# RZN2L register map
Vendor: Renesas Electronics Corporation; Series: RZN; File version: 1.30.01
CPU: other r0p0, little endian, MPU, no FPU, VTOR, 4 interrupt priority bits, 624 interrupts
Registers are 32-bit, read-write, reset 0x0 unless marked. A register's access mark holds for its fields unless they carry their own. Offsets are from the block's base; [hi:lo] are bit positions; {n}, {i} and the like mark numbered series; 'fields as' and 'values as' point back to an identical list.

## ELC — Evnet Link Controller
Base 0x80090010
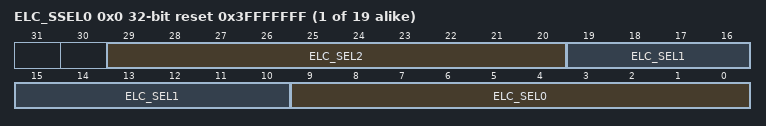
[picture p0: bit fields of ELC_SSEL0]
{0x0+4i} ELC_SSEL{i} (i=0..18) reset 0x3FFFFFFF — ELC Event Source Select Register {i}
  [29:20] ELC_SEL2 — Set the number for ELC event source to be linked to the ELC destination.
  [19:10] ELC_SEL1 — Set the number for ELC event source to be linked to the ELC destination.
  [9:0] ELC_SEL0 — Set the number for ELC event source to be linked to the ELC destination.

## DMA — DMAC Configuration
Base 0x80090060
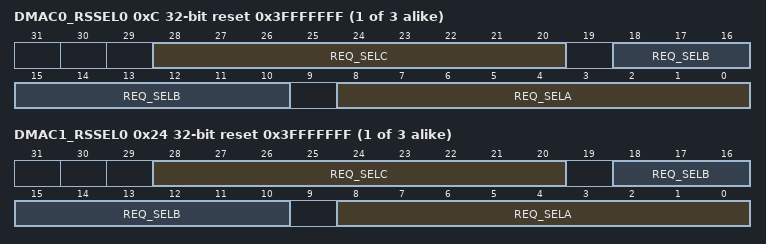
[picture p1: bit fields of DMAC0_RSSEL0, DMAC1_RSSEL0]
{0xC+4i} DMAC0_RSSEL{i} (i=0..2) reset 0x3FFFFFFF — DMAC Unit 0 Resource Select Register {i}
  [28:20] REQ_SELC — DMA Resource Select for Channel n + 2
  [18:10] REQ_SELB — DMA Resource Select for Channel n + 1
  [8:0] REQ_SELA — DMA Resource Select for Channel n
{0x24+4i} DMAC1_RSSEL{i} (i=0..2) reset 0x3FFFFFFF — DMAC Unit 1 Resource Select Register {i}
  fields as DMAC0_RSSEL0

## ESC_INI — Initial Configuration 1 for EtherCAT Slave Controller
Base 0x80110200
0x00 ECATOFFADR — EtherCAT PHY Offset Address Setting Register
  [4:0] OADD — PHY Offset Address Setting
0x04 ECATOPMOD — EtherCAT Operation Mode Register
  [0] EEPROMSIZE — EEPROM Memory Size Specification
    0=16 Kbits or less; 1=32 Kbits to 4 Mbits
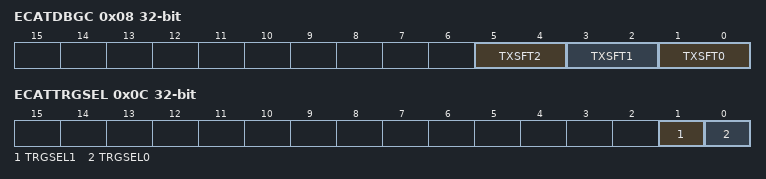
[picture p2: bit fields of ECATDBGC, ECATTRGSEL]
0x08 ECATDBGC — EtherCAT Debug Control Register
  [all] fields
    0=0 ns; 1=10 ns; 2=20 ns; 3=30 ns
  [5:4] TXSFT2 — Set the delay time for ETH2_TXEN and ETH2_TXDn of the EtherCAT
  [3:2] TXSFT1 — Set the delay time for ETH1_TXEN and ETH1_TXDn of the EtherCAT
  [1:0] TXSFT0 — Set the delay time for ETH0_TXEN and ETH0_TXDn of the EtherCAT
0x0C ECATTRGSEL — EtherCAT DC Latch Trigger Select Register
  [1] TRGSEL1 — Select DC Latch Trigger 1 for ESC
    0=Select LATCH1 input from ELC; 1=Select LATCH1 input from external
  [0] TRGSEL0 — Select DC Latch Trigger 0 for ESC
    0=Select LATCH0 input from ELC; 1=Select LATCH0 input from external

## ETHSW_PTP — Ethernet Switch for PTP
Base 0x80110400
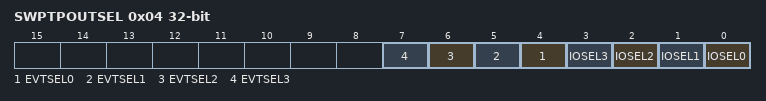
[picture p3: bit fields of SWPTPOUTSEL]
0x04 SWPTPOUTSEL — ETHSW_PTPOUT Select Register
  [n+4] EVTSEL{n} (n=0..3) — Select the source of the ETHSW_PTPOUT{n} event for GIC, DMAC, and ELC
    0=Pulse generator {n} output; 1=TDMA_GPIO[{n+4}] output
  [n] IOSEL{n} (n=0..3) — Select the source of the ETHSW_PTPOUT{n} output signal
    0=Pulse generator {n} output; 1=TDMA_GPIO[{n+4}] output
{0x400+0x100*i} SWTMEN{i} (i=0..3) — PTP Timer Pulse Output Enable {i} Register
  [0] OUTEN — Enable ETHSW_PTPOUTn Signal Output
    0=Disabled; 1=Enabled
{0x404+0x100*i} SWTMSTSEC{i} (i=0..3) — PTP Timer Pulse Start Second {i} Register
  [31:0] STSEC
{0x408+0x100*i} SWTMSTNS{i} (i=0..3) — PTP Timer Pulse Start Nanosecond {i} Register
  [31:0] STNS — Start Time by Nanosecond
{0x40C+0x100*i} SWTMPSEC{i} (i=0..3) — PTP Timer Pulse Period Second {i} Register
  [31:0] PSEC
{0x410+0x100*i} SWTMPNS{i} (i=0..3) reset 0x3B9ACA00 — PTP Timer Pulse Period Nanosecond {i} Register
  [31:0] PNS — Period by Nanosecond
{0x414+0x100*i} SWTMWTH{i} (i=0..3) reset 0x3 — PTP Timer Pulse Width {i} Register
  [15:0] WIDTH — Set the Pulse Width of ETHSW_PTPOUTn in the cycle number of ts_clk (8 ns).
{0x418+0x100*i} SWTMMAXP{i} (i=0..3) reset 0x3B9ACA00 — PTP Timer Pulse Max Nanosecond {i} Register
  [31:0] MAXP — Sets the boundary value in nanoseconds to carry from the nanosecond field to the second field. The same value as ATIME_EVT_PERIOD register must be set.
{0x41C+0x100*i} SWTMLATSEC{i} (i=0..3) — PTP Timer Pulse Latch Second {i} Register
  [31:0] LATSEC
{0x420+0x100*i} SWTMLATNS{i} (i=0..3) — PTP Timer Pulse Latch Nanosecond {i} Register
  [31:0] LATNS

## MBXSEM — Mailbox and Semaphore
Base 0x80240000
{0x0+4i} SEM{i} (i=0..7) — Semaphore Register {i}
  [0] SEM — Semaphore bit
    0=Resource being used; 1=Resource not being used
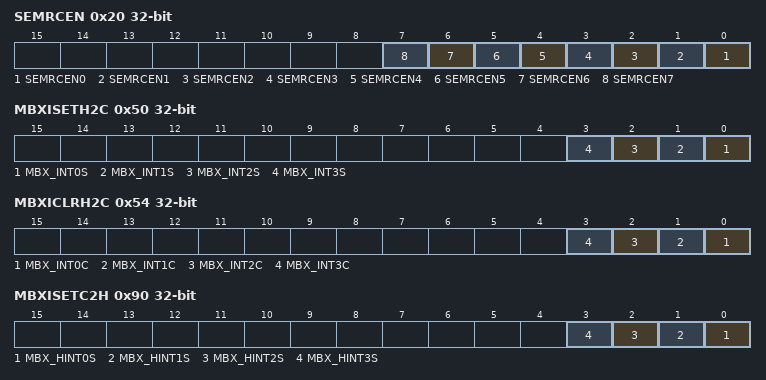
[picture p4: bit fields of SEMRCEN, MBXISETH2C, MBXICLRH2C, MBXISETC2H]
0x20 SEMRCEN — Semaphore Read Clear Enable Register
  [all] fields
    0=Disables read clear function; 1=Enables read clear function
  [n] SEMRCEN{n} (n=0..7)
{0x40+4i} MBXH2C{i} (i=0..3) ro — Host to CR52 Mailbox Register {i}
  [31:0] MBX
0x50 MBXISETH2C ro — Host to CR52 Mailbox Interrupt Set Register
  [n] MBX_INT{n}S (n=0..3) — Generates or indicates MBX_INT{n} interrupt of mailbox from external host CPU to internal Cortex-R52.
0x54 MBXICLRH2C — Host to CR52 Mailbox Interrupt Clear Register
  [n] MBX_INT{n}C (n=0..3) — Clears or indicates MBX_INT{n} interrupt of mailbox from external host CPU to internal Cortex-R52.
{0x80+4i} MBXC2H{i} (i=0..3) — CR52 to Host Mailbox Register {i}
  [31:0] MBX
0x90 MBXISETC2H — CR52 to Host Mailbox Interrupt Set Register
  [n] MBX_HINT{n}S (n=0..3) — Generates or indicates MBX_HINT{n} interrupt of mailbox from internal Cortex-R52 to external host CPU.
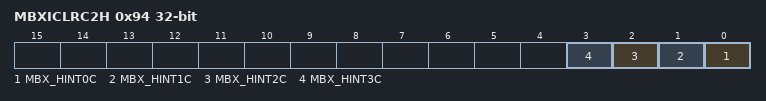
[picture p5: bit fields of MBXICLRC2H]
0x94 MBXICLRC2H ro — CR52 to Host Mailbox Interrupt Clear Register
  [n] MBX_HINT{n}C (n=0..3) — Clears or indicates MBX_HINT{n} interrupt of mailbox from internal Cortex-R52 to external host CPU.
